# ATSAM3U2E device description
Architecture: CORTEX-M3; Family: SAM3; Series: SAM3U
Registers are 32-bit, read-write, no defined reset value unless marked. A register's access mark holds for its fields unless they carry their own. Offsets are from the block's base; [hi:lo] are bit positions; {n}, {i} and the like mark numbered series.

## UDPHS — USB High Speed Device Port
Instances: UDPHS 0x400A4000
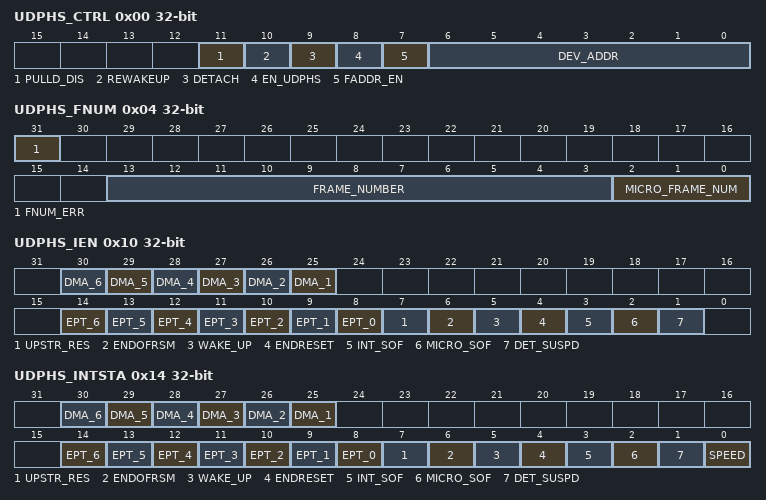
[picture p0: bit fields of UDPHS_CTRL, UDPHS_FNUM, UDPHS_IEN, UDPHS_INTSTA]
0x00 UDPHS_CTRL — UDPHS Control Register
  [11] PULLD_DIS — Pull-Down Disable
  [10] REWAKEUP — Send Remote Wake Up
  [9] DETACH — Detach Command
  [8] EN_UDPHS — UDPHS Enable
  [7] FADDR_EN — Function Address Enable
  [6:0] DEV_ADDR — UDPHS Address
0x04 UDPHS_FNUM ro — UDPHS Frame Number Register
  [31] FNUM_ERR — Frame Number CRC Error
  [13:3] FRAME_NUMBER — Frame Number as defined in the Packet Field Formats
  [2:0] MICRO_FRAME_NUM — Microframe Number
0x10 UDPHS_IEN — UDPHS Interrupt Enable Register
  [n+24] DMA_{n} (n=1..6) — DMA Channel {n} Interrupt Enable
  [n+8] EPT_{n} (n=0..6) — Endpoint {n} Interrupt Enable
  [7] UPSTR_RES — Upstream Resume Interrupt Enable
  [6] ENDOFRSM — End Of Resume Interrupt Enable
  [5] WAKE_UP — Wake Up CPU Interrupt Enable
  [4] ENDRESET — End Of Reset Interrupt Enable
  [3] INT_SOF — SOF Interrupt Enable
  [2] MICRO_SOF — Micro-SOF Interrupt Enable
  [1] DET_SUSPD — Suspend Interrupt Enable
0x14 UDPHS_INTSTA ro — UDPHS Interrupt Status Register
  [n+24] DMA_{n} (n=1..6) — DMA Channel {n} Interrupt
  [n+8] EPT_{n} (n=0..6) — Endpoint {n} Interrupt
  [7] UPSTR_RES — Upstream Resume Interrupt
  [6] ENDOFRSM — End Of Resume Interrupt
  [5] WAKE_UP — Wake Up CPU Interrupt
  [4] ENDRESET — End Of Reset Interrupt
  [3] INT_SOF — Start Of Frame Interrupt
  [2] MICRO_SOF — Micro Start Of Frame Interrupt
  [1] DET_SUSPD — Suspend Interrupt
  [0] SPEED — Speed Status
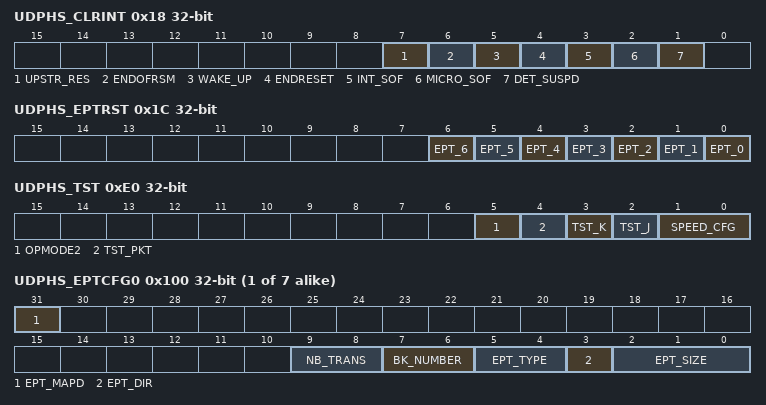
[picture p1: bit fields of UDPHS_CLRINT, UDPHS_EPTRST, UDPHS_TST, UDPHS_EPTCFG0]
0x18 UDPHS_CLRINT wo — UDPHS Clear Interrupt Register
  [7] UPSTR_RES — Upstream Resume Interrupt Clear
  [6] ENDOFRSM — End Of Resume Interrupt Clear
  [5] WAKE_UP — Wake Up CPU Interrupt Clear
  [4] ENDRESET — End Of Reset Interrupt Clear
  [3] INT_SOF — Start Of Frame Interrupt Clear
  [2] MICRO_SOF — Micro Start Of Frame Interrupt Clear
  [1] DET_SUSPD — Suspend Interrupt Clear
0x1C UDPHS_EPTRST wo — UDPHS Endpoints Reset Register
  [n] EPT_{n} (n=0..6) — Endpoint {n} Reset
0xE0 UDPHS_TST — UDPHS Test Register
  [5] OPMODE2
  [4] TST_PKT — Test Packet Mode
  [3] TST_K — Test K Mode
  [2] TST_J — Test J Mode
  [1:0] SPEED_CFG — Speed Configuration
    0=NORMAL (Normal Mode: The macro is in Full Speed mode, ready to make a High Speed identification, if the host supports it and then to automatically switch to High Speed mode); 2=HIGH_SPEED (Force High Speed: Set this value to force the hardware to work in High Speed mode. Only for debug or test purpose.); 3=FULL_SPEED (Force Full Speed: Set this value to force the hardware to work only in Full Speed mode. In this configuration, the macro will not respond to a High Speed reset handshake.)
{0x100+0x20*i} UDPHS_EPTCFG{i} (i=0..6) — UDPHS Endpoint Configuration Register (endpoint = {i})
  [31] EPT_MAPD — Endpoint Mapped
  [9:8] NB_TRANS — Number Of Transaction per Microframe
  [7:6] BK_NUMBER — Number of Banks
    0=Zero bank, the endpoint is not mapped in memory; 1=One bank (bank 0); 2=Double bank (Ping-Pong: bank0/bank1); 3=Triple bank (bank0/bank1/bank2)
  [5:4] EPT_TYPE — Endpoint Type
    0=CTRL8 (Control endpoint); 1=ISO (Isochronous endpoint); 2=BULK (Bulk endpoint); 3=INT (Interrupt endpoint)
  [3] EPT_DIR — Endpoint Direction
  [2:0] EPT_SIZE — Endpoint Size
    0=8 bytes; 1=16 bytes; 2=32 bytes; 3=64 bytes; 4=128 bytes; 5=256 bytes; 6=512 bytes; 7=1024 bytes
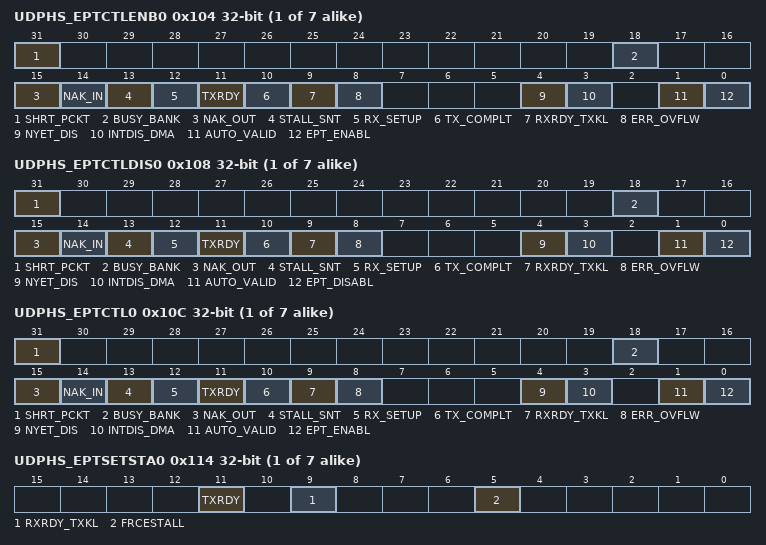
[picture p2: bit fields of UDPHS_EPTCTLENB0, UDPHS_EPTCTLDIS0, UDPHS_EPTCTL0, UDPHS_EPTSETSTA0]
{0x104+0x20*i} UDPHS_EPTCTLENB{i} wo (i=0..6) — UDPHS Endpoint Control Enable Register (endpoint = {i})
  [31] SHRT_PCKT — Short Packet Send/Short Packet Interrupt Enable
  [18] BUSY_BANK — Busy Bank Interrupt Enable
  [15] NAK_OUT — NAKOUT Interrupt Enable
  [14] NAK_IN — NAKIN Interrupt Enable
  [13] STALL_SNT — Stall Sent Interrupt Enable
  [12] RX_SETUP — Received SETUP
  [11] TXRDY — TX Packet Ready Interrupt Enable
  [10] TX_COMPLT — Transmitted IN Data Complete Interrupt Enable
  [9] RXRDY_TXKL — Received OUT Data Interrupt Enable
  [8] ERR_OVFLW — Overflow Error Interrupt Enable
  [4] NYET_DIS — NYET Disable (Only for High Speed Bulk OUT endpoints)
  [3] INTDIS_DMA — Interrupts Disable DMA
  [1] AUTO_VALID — Packet Auto-Valid Enable
  [0] EPT_ENABL — Endpoint Enable
{0x108+0x20*i} UDPHS_EPTCTLDIS{i} wo (i=0..6) — UDPHS Endpoint Control Disable Register (endpoint = {i})
  [31] SHRT_PCKT — Short Packet Interrupt Disable
  [18] BUSY_BANK — Busy Bank Interrupt Disable
  [15] NAK_OUT — NAKOUT Interrupt Disable
  [14] NAK_IN — NAKIN Interrupt Disable
  [13] STALL_SNT — Stall Sent Interrupt Disable
  [12] RX_SETUP — Received SETUP Interrupt Disable
  [11] TXRDY — TX Packet Ready Interrupt Disable
  [10] TX_COMPLT — Transmitted IN Data Complete Interrupt Disable
  [9] RXRDY_TXKL — Received OUT Data Interrupt Disable
  [8] ERR_OVFLW — Overflow Error Interrupt Disable
  [4] NYET_DIS — NYET Enable (Only for High Speed Bulk OUT endpoints)
  [3] INTDIS_DMA — Interrupts Disable DMA
  [1] AUTO_VALID — Packet Auto-Valid Disable
  [0] EPT_DISABL — Endpoint Disable
{0x10C+0x20*i} UDPHS_EPTCTL{i} ro (i=0..6) — UDPHS Endpoint Control Register (endpoint = {i})
  [31] SHRT_PCKT — Short Packet Interrupt Enabled
  [18] BUSY_BANK — Busy Bank Interrupt Enabled
  [15] NAK_OUT — NAKOUT Interrupt Enabled
  [14] NAK_IN — NAKIN Interrupt Enabled
  [13] STALL_SNT — Stall Sent Interrupt Enabled
  [12] RX_SETUP — Received SETUP Interrupt Enabled
  [11] TXRDY — TX Packet Ready Interrupt Enabled
  [10] TX_COMPLT — Transmitted IN Data Complete Interrupt Enabled
  [9] RXRDY_TXKL — Received OUT Data Interrupt Enabled
  [8] ERR_OVFLW — Overflow Error Interrupt Enabled
  [4] NYET_DIS — NYET Disable (Only for High Speed Bulk OUT endpoints)
  [3] INTDIS_DMA — Interrupt Disables DMA
  [1] AUTO_VALID — Packet Auto-Valid Enabled (Not for CONTROL Endpoints)
  [0] EPT_ENABL — Endpoint Enable
{0x114+0x20*i} UDPHS_EPTSETSTA{i} wo (i=0..6) — UDPHS Endpoint Set Status Register (endpoint = {i})
  [11] TXRDY — TX Packet Ready Set
  [9] RXRDY_TXKL — KILL Bank Set (for IN Endpoint)
  [5] FRCESTALL — Stall Handshake Request Set
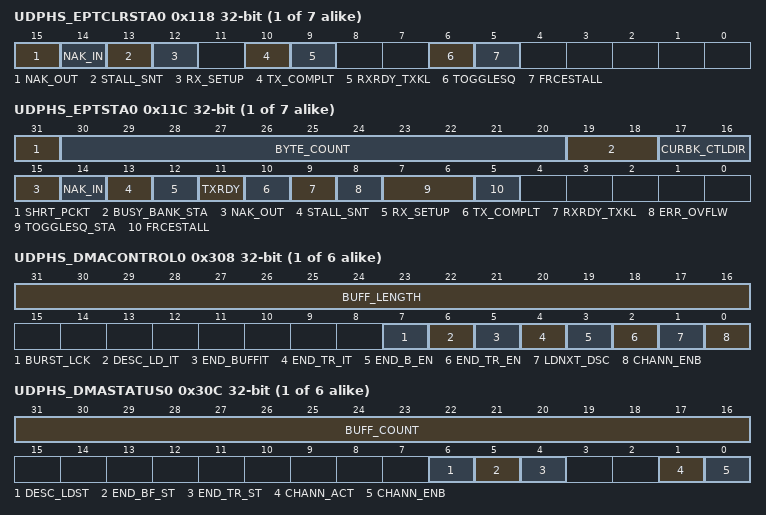
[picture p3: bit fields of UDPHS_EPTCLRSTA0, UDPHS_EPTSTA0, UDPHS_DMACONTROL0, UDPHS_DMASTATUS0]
{0x118+0x20*i} UDPHS_EPTCLRSTA{i} wo (i=0..6) — UDPHS Endpoint Clear Status Register (endpoint = {i})
  [15] NAK_OUT — NAKOUT Clear
  [14] NAK_IN — NAKIN Clear
  [13] STALL_SNT — Stall Sent Clear
  [12] RX_SETUP — Received SETUP Clear
  [10] TX_COMPLT — Transmitted IN Data Complete Clear
  [9] RXRDY_TXKL — Received OUT Data Clear
  [6] TOGGLESQ — Data Toggle Clear
  [5] FRCESTALL — Stall Handshake Request Clear
{0x11C+0x20*i} UDPHS_EPTSTA{i} ro (i=0..6) — UDPHS Endpoint Status Register (endpoint = {i})
  [31] SHRT_PCKT — Short Packet
  [30:20] BYTE_COUNT — UDPHS Byte Count
  [19:18] BUSY_BANK_STA — Busy Bank Number
    0=_1BUSYBANK; 1=_2BUSYBANKS; 2=_3BUSYBANKS
  [17:16] CURBK_CTLDIR — Current Bank/Control Direction
  [15] NAK_OUT
  [14] NAK_IN
  [13] STALL_SNT — Stall Sent
  [12] RX_SETUP — Received SETUP
  [11] TXRDY — TX Packet Ready
  [10] TX_COMPLT — Transmitted IN Data Complete
  [9] RXRDY_TXKL — Received OUT Data/KILL Bank
  [8] ERR_OVFLW — Overflow Error
  [7:6] TOGGLESQ_STA — Toggle Sequencing
    0=DATA0; 1=DATA1; 2=DATA2 (Reserved for High Bandwidth Isochronous Endpoint); 3=MDATA (Reserved for High Bandwidth Isochronous Endpoint)
  [5] FRCESTALL — Stall Handshake Request
{0x300+0x10*i} UDPHS_DMANXTDSC{i} (i=0..5) — UDPHS DMA Next Descriptor Address Register (channel = {i})
  [31:0] NXT_DSC_ADD — Next Descriptor Address
{0x304+0x10*i} UDPHS_DMAADDRESS{i} (i=0..5) — UDPHS DMA Channel Address Register (channel = {i})
  [31:0] BUFF_ADD — Buffer Address
{0x308+0x10*i} UDPHS_DMACONTROL{i} (i=0..5) — UDPHS DMA Channel Control Register (channel = {i})
  [31:16] BUFF_LENGTH — Buffer Byte Length (Write-only)
  [7] BURST_LCK — Burst Lock Enable
  [6] DESC_LD_IT — Descriptor Loaded Interrupt Enable
  [5] END_BUFFIT — End of Buffer Interrupt Enable
  [4] END_TR_IT — End of Transfer Interrupt Enable
  [3] END_B_EN — End of Buffer Enable (Control)
  [2] END_TR_EN — End of Transfer Enable (Control)
  [1] LDNXT_DSC — Load Next Channel Transfer Descriptor Enable (Command)
  [0] CHANN_ENB — (Channel Enable Command)
{0x30C+0x10*i} UDPHS_DMASTATUS{i} (i=0..5) — UDPHS DMA Channel Status Register (channel = {i})
  [31:16] BUFF_COUNT — Buffer Byte Count
  [6] DESC_LDST — Descriptor Loaded Status
  [5] END_BF_ST — End of Channel Buffer Status
  [4] END_TR_ST — End of Channel Transfer Status
  [1] CHANN_ACT — Channel Active Status
  [0] CHANN_ENB — Channel Enable Status

## Notices in the file
SAM Software Package License
Copyright (c) %copyright_year%, Atmel Corporation
All rights reserved.
Redistribution and use in source and binary forms, with or without
modification, are permitted provided that the following condition is met:
- Redistributions of source code must retain the above copyright notice,
this list of conditions and the disclaimer below.
Atmel's name may not be used to endorse or promote products derived from
this software without specific prior written permission.
DISCLAIMER:  THIS SOFTWARE IS PROVIDED BY ATMEL "AS IS" AND ANY EXPRESS OR
IMPLIED WARRANTIES, INCLUDING, BUT NOT LIMITED TO, THE IMPLIED WARRANTIES OF
MERCHANTABILITY, FITNESS FOR A PARTICULAR PURPOSE AND NON-INFRINGEMENT ARE
DISCLAIMED. IN NO EVENT SHALL ATMEL BE LIABLE FOR ANY DIRECT, INDIRECT,
INCIDENTAL, SPECIAL, EXEMPLARY, OR CONSEQUENTIAL DAMAGES (INCLUDING, BUT NOT
LIMITED TO, PROCUREMENT OF SUBSTITUTE GOODS OR SERVICES; LOSS OF USE, DATA,
OR PROFITS; OR BUSINESS INTERRUPTION) HOWEVER CAUSED AND ON ANY THEORY OF
LIABILITY, WHETHER IN CONTRACT, STRICT LIABILITY, OR TORT (INCLUDING
NEGLIGENCE OR OTHERWISE) ARISING IN ANY WAY OUT OF THE USE OF THIS SOFTWARE,
EVEN IF ADVISED OF THE POSSIBILITY OF SUCH DAMAGE.
